VERSION ""

NS_ :

BS_:
BU_:
BO_ 706 Battery: 4 Vector__XXX
   SG_ Battery_Voltage : 23|8@0+ (0.1,0) [0|1] "" Vector__XXX

BO_ 792 SteeringWheelButtons: 8 Vector__XXX

BO_ 826 Cabin_Temp: 8 Vector__XXX
   SG_ Interior_Temp : 7|16@0+ (0.01,-40) [0|1] "C" Vector__XXX

BO_ 1100 Config6: 8 Vector__XXX
   SG_ Config6 : 7|64@0+ (1,0) [0|1] "" Vector__XXX

BO_ 1098 Config5: 8 Vector__XXX
   SG_ Config5 : 7|64@0+ (1,0) [0|1] "" Vector__XXX

BO_ 992 VIN: 8 Vector__XXX
   SG_ VIN_MsgNo : 7|8@0+ (1,0) [0|1] "" Vector__XXX
   SG_ VIN : 15|56@4- (1,0) [0|1] "" Vector__XXX

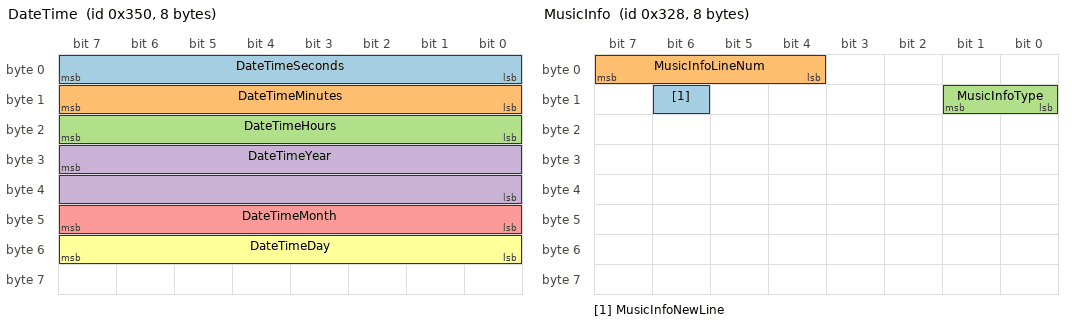
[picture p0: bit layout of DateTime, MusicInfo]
BO_ 848 DateTime: 8 Vector__XXX
   SG_ DateTimeSeconds : 7|8@0+ (1,0) [0|1] "" Vector__XXX
   SG_ DateTimeMinutes : 15|8@0+ (1,0) [0|1] "" Vector__XXX
   SG_ DateTimeHours : 23|8@0+ (1,0) [0|1] "" Vector__XXX
   SG_ DateTimeYear : 31|16@0+ (1,0) [0|1] "" Vector__XXX
   SG_ DateTimeMonth : 47|8@0+ (1,0) [0|1] "" Vector__XXX
   SG_ DateTimeDay : 55|8@0+ (1,0) [0|1] "" Vector__XXX

BO_ 978 Odometer: 4 Vector__XXX
   SG_ Odometer : 7|24@0+ (0.1,0) [0|1] "km" Vector__XXX

BO_ 832 GearSpeed: 8 Vector__XXX
   SG_ Gear : 23|8@0+ (1,0) [0|1] "" Vector__XXX
   SG_ Gear70 : 31|24@0+ (1,0) [0|1] "" Vector__XXX

BO_ 810 MeasurementUnits: 8 Vector__XXX

BO_ 808 MusicInfo: 8 Vector__XXX
   SG_ MusicInfoNewLine : 14|1@0+ (1,0) [0|1] "" Vector__XXX
   SG_ MusicInfoLineNum : 7|4@0+ (1,0) [0|1] "" Vector__XXX
   SG_ MusicInfoText : 23|48@4- (1,0) [0|1] "" Vector__XXX
   SG_ MusicInfoType : 9|2@0+ (1,0) [0|1] "" Vector__XXX

BO_ 802 RpmSpeed: 8 Vector__XXX
   SG_ Speed : 23|16@0+ (0.05,0) [0|1] "" Vector__XXX
   SG_ Rpm : 7|16@0+ (1,0) [0|1] "" Vector__XXX

BO_ 778 Temperatures: 8 Vector__XXX
   SG_ Temperatures1 : 7|16@0+ (1,0) [0|1] "" Vector__XXX
   SG_ TemperaturesSig37218 : 39|32@0+ (1,0) [0|1] "" Vector__XXX

BO_ 2147484205 SteeringButtons: 8 Vector__XXX

BO_ 2147483938 IgnitionOrEngineRun: 4 Vector__XXX

BO_ 2147483947 IgnOrEngineRunStatus: 1 Vector__XXX

BO_ 2147484096 Constant: 1 Vector__XXX

BO_ 2147484104 Constant: 8 Vector__XXX

BO_ 2147484207 IgnOrRunStatus: 1 Vector__XXX

BO_ 2147484208 Temperature: 8 Vector__XXX

BO_ 2147484210 Unknown: 8 Vector__XXX
   SG_ TransTemp : 15|8@0+ (1,-40) [0|1] "" Vector__XXX

BO_ 2147484227 Empty: 6 Vector__XXX

BO_ 2147484275 Empty: 6 Vector__XXX

BO_ 2147484355 Unknown: 4 Vector__XXX

BO_ 2147484372 Empty: 8 Vector__XXX

BO_ 2147484466 TransmissionPosition: 8 Vector__XXX
   SG_ TransmissionPositionSig219 : 15|8@4- (1,0) [0|1] "" Vector__XXX

BO_ 2147484504 Transmission: 4 Vector__XXX

BO_ 2147484506 WiFi: 8 Vector__XXX
   SG_ WiFiSig167 : 7|56@4- (1,0) [0|1] "" Vector__XXX

BO_ 2147484604 StreetName: 8 Vector__XXX

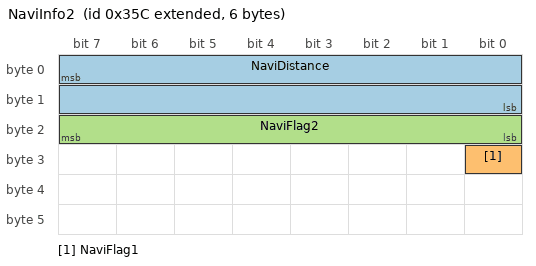
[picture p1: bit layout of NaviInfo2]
BO_ 2147484508 NaviInfo2: 6 Vector__XXX
   SG_ NaviDistance : 7|16@0+ (1,0) [0|1] "" Vector__XXX
   SG_ NaviFlag1 : 24|1@0+ (1,0) [0|1] "" Vector__XXX
   SG_ NaviFlag2 : 23|8@0+ (1,0) [0|1] "" Vector__XXX

BO_ 2147485631 RadioModuleTx: 8 Vector__XXX

BO_ 2147485514 SwayBarModuleTx: 8 Vector__XXX

BO_ 2147484991 RadioModuleRx: 8 Vector__XXX

BO_ 2147484874 SwayBarModuleRx: 8 Vector__XXX

BO_ 2147484371 ConsoleButtons: 8 Vector__XXX
   SG_ TractionControlButton : 56|1@0+ (1,0) [0|1] "" Vector__XXX
   SG_ ESSButton : 15|8@0+ (1,0) [0|1] "" Vector__XXX

BO_ 2147484410 DoorsAndInterior: 8 Vector__XXX
   SG_ DriverDoorOpen : 0|1@0+ (1,0) [0|1] "" Vector__XXX

BO_ 2147485586 UnknownModuleTx: 8 Vector__XXX

BO_ 2147484946 UnknownModuleRx: 8 Vector__XXX

BO_ 2147485167 UnknownModule: 8 Vector__XXX

BO_ 2147485630 AmplifierTx: 8 Vector__XXX

BO_ 2147485593 RightBlindSpotTx: 8 Vector__XXX

BO_ 2147485588 VisionModuleTx: 8 Vector__XXX

BO_ 2147485585 LeftBlindSpotTx: 8 Vector__XXX

BO_ 2147485571 HVACModuleTx: 8 Vector__XXX

BO_ 2147484990 AmplifierRx: 8 Vector__XXX

BO_ 2147484953 RightBlindSpotRx: 8 Vector__XXX

BO_ 2147484945 LeftBlindSpotRx: 8 Vector__XXX

BO_ 2147484948 VisionModuleRx: 8 Vector__XXX

BO_ 2147484931 HVACModuleRx: 8 Vector__XXX

BA_DEF_ BO_ "GenMsgBackgroundColor" STRING ;
BA_DEF_ BO_ "GenMsgForegroundColor" STRING ;
BA_DEF_ BO_ "filterlabeling" INT 0 0;
BA_DEF_ BO_ "filterlabeling" INT 0 0;
BA_DEF_ BO_ "filterlabeling" INT 0 0;
BA_DEF_ BO_ "filterlabeling" INT 0 0;
BA_DEF_ BO_ "filterlabeling" INT 0 0;
BA_DEF_ BO_ "filterlabeling" INT 0 0;
BA_DEF_ BO_ "filterlabeling" INT 0 0;
BA_DEF_ BO_ "filterlabeling" INT 0 0;
BA_DEF_ BO_ "filterlabeling" INT 0 0;
BA_DEF_ BO_ "filterlabeling" INT 0 0;
BA_DEF_ BO_ "filterlabeling" INT 0 0;
BA_DEF_ BO_ "filterlabeling" INT 0 0;
BA_DEF_ BO_ "filterlabeling" INT 0 0;
BA_DEF_ BO_ "filterlabeling" INT 0 0;
BA_DEF_ BO_ "filterlabeling" INT 0 0;
BA_DEF_ BO_ "filterlabeling" INT 0 0;
BA_DEF_ BO_ "filterlabeling" INT 0 0;
BA_DEF_ BO_ "filterlabeling" INT 0 0;
BA_DEF_ BO_ "filterlabeling" INT 0 0;
BA_DEF_ BO_ "filterlabeling" INT 0 0;
BA_DEF_DEF_ "GenMsgBackgroundColor" "#ffffff";
BA_DEF_DEF_ "GenMsgForegroundColor" "#000000";
BA_DEF_DEF_ "filterlabeling" 1;
BA_DEF_DEF_ "filterlabeling" 1;
BA_ "GenMsgBackgroundColor" BO_ 808 "#ffff7f";
BA_ "GenMsgForegroundColor" BO_ 2147485631 "#00aa00";
BA_ "GenMsgForegroundColor" BO_ 2147484991 "#00aa7f";
VAL_ 832 Gear 61 "Park" 0 "No Description";
VAL_ 832 Gear70 61 "Park" 0 "No Description";
